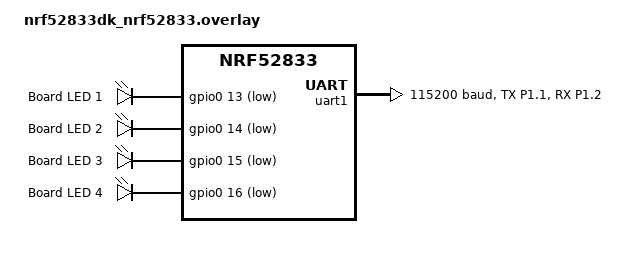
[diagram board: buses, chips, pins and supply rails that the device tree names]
/* boards/nrf52833dk_nrf52833.overlay */
#include <zephyr/dt-bindings/pinctrl/nrf-pinctrl.h>
/ {
    leds {
        compatible = "gpio-leds";
        board_led_1: board_led_p0_13 {
            gpios = <&gpio0 13 GPIO_ACTIVE_LOW>;
            label = "Board LED 1";
        };

        board_led_2: board_led_p0_14 {
            gpios = <&gpio0 14 GPIO_ACTIVE_LOW>;
            label = "Board LED 2";
        };

        board_led_3: board_led_p0_15 {
            gpios = <&gpio0 15 GPIO_ACTIVE_LOW>;
            label = "Board LED 3";
        };

        board_led_4: board_led_p0_16 {
            gpios = <&gpio0 16 GPIO_ACTIVE_LOW>;
            label = "Board LED 4";
        };
    };

    aliases {
        led1 = &board_led_1;
        led2 = &board_led_2;
        led3 = &board_led_3;
        led4 = &board_led_4;
    };
};

&pinctrl {
    uart1_default: uart1_default {
        group1 {
            psels = <NRF_PSEL(UART_TX, 1, 1)>,
                    <NRF_PSEL(UART_RX, 1, 2)>;
        };
    };

    uart1_sleep: uart1_sleep {
        group1 {
            psels = <NRF_PSEL(UART_TX, 1, 1)>,
                    <NRF_PSEL(UART_RX, 1, 2)>;
            low-power-enable;
        };
    };
};

&uart1 {
    status = "okay";
    current-speed = <115200>;
    pinctrl-0 = <&uart1_default>;
    pinctrl-1 = <&uart1_sleep>;
    pinctrl-names = "default", "sleep";
};
